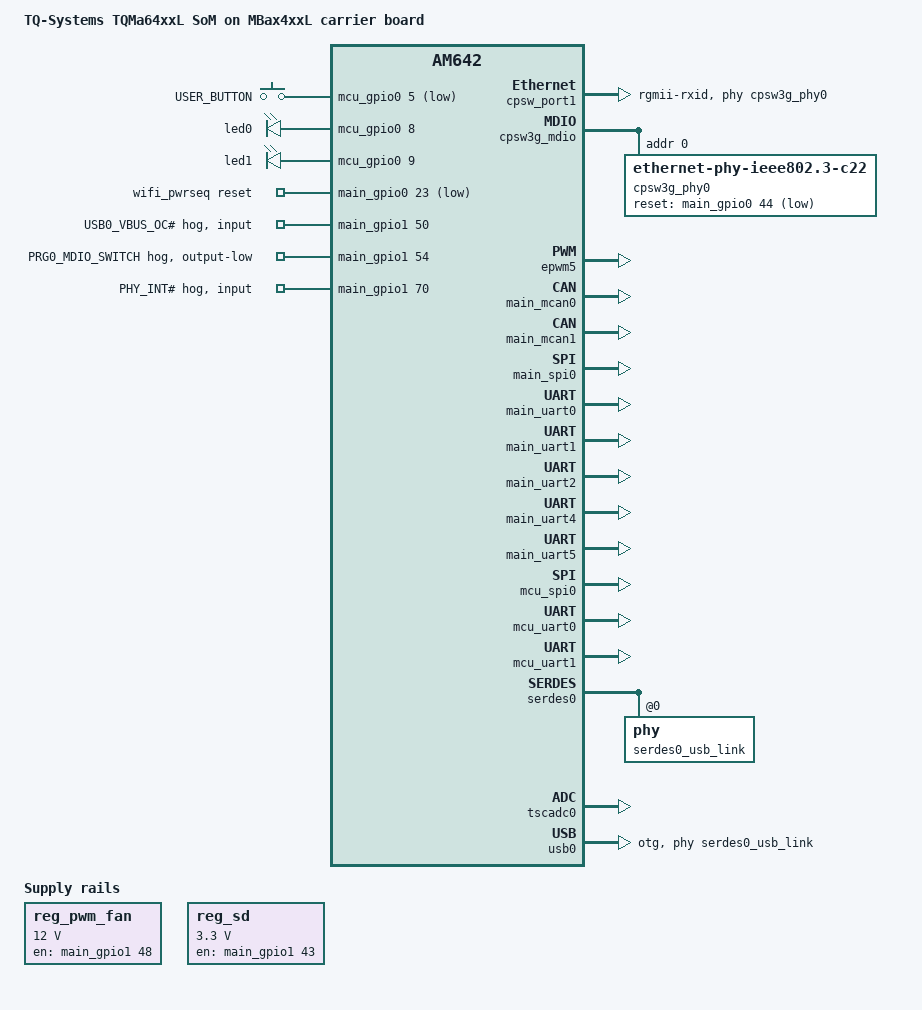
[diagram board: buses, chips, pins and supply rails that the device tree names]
/dts-v1/;
#include <dt-bindings/gpio/gpio.h>
#include <dt-bindings/input/input.h>
#include <dt-bindings/net/ti-dp83867.h>
#include <dt-bindings/phy/phy.h>
#include <dt-bindings/pwm/pwm.h>
#include "k3-serdes.h"
#include "k3-am642-tqma64xxl.dtsi"
/ {
	compatible = "tq,am642-tqma6442l-mbax4xxl", "tq,am642-tqma6442l",
		     "ti,am642";
	model = "TQ-Systems TQMa64xxL SoM on MBax4xxL carrier board";
	aliases {
		ethernet0 = &cpsw_port1;
		i2c1 = &mcu_i2c0;
		mmc1 = &sdhci1;
		serial0 = &mcu_uart0;
		serial1 = &mcu_uart1;
		serial2 = &main_uart0;
		serial3 = &main_uart1;
		serial4 = &main_uart2;
		serial5 = &main_uart4;
		serial6 = &main_uart5;
		serial7 = &main_uart3;
		spi1 = &main_spi0;
		spi2 = &mcu_spi0;
	};
	chosen {
		stdout-path = &main_uart0;
	};
	gpio-keys {
		compatible = "gpio-keys";
		pinctrl-names = "default";
		pinctrl-0 = <&mcu_gpio_keys_pins>;
		user-button {
			label = "USER_BUTTON";
			linux,code = <BTN_0>;
			gpios = <&mcu_gpio0 5 GPIO_ACTIVE_LOW>;
		};
	};
	gpio-leds {
		compatible = "gpio-leds";
		pinctrl-names = "default";
		pinctrl-0 = <&mcu_gpio_leds_pins>;
		led-0 {
			label = "led0";
			gpios = <&mcu_gpio0 8 GPIO_ACTIVE_HIGH>;
		};
		led-1 {
			label = "led1";
			gpios = <&mcu_gpio0 9 GPIO_ACTIVE_HIGH>;
		};
	};
	fan0: pwm-fan {
		compatible = "pwm-fan";
		pinctrl-names = "default";
		pinctrl-0 = <&pwm_fan_pins>;
		fan-supply = <&reg_pwm_fan>;
		#cooling-cells = <2>;
		pwms = <&epwm5 0 40000 PWM_POLARITY_INVERTED>;
		cooling-levels = <0 32 64 128 196 240>;
		pulses-per-revolution = <2>;
		interrupt-parent = <&main_gpio1>;
		interrupts = <49 IRQ_TYPE_EDGE_FALLING>;
		status = "disabled";
	};
	wifi_pwrseq: pwrseq-wifi {
		compatible = "mmc-pwrseq-simple";
		pinctrl-names = "default";
		pinctrl-0 = <&main_mmc1_wifi_pwrseq_pins>;
		reset-gpios = <&main_gpio0 23 GPIO_ACTIVE_LOW>;
	};
	reg_pwm_fan: regulator-pwm-fan {
		compatible = "regulator-fixed";
		pinctrl-names = "default";
		pinctrl-0 = <&pwm_fan_reg_pins>;
		regulator-name = "FAN_PWR";
		regulator-min-microvolt = <12000000>;
		regulator-max-microvolt = <12000000>;
		gpio = <&main_gpio1 48 GPIO_ACTIVE_HIGH>;
		enable-active-high;
	};
	reg_sd: regulator-sd {
		compatible = "regulator-fixed";
		pinctrl-names = "default";
		pinctrl-0 = <&main_mmc1_reg_pins>;
		regulator-name = "V_3V3_SD";
		regulator-min-microvolt = <3300000>;
		regulator-max-microvolt = <3300000>;
		gpio = <&main_gpio1 43 GPIO_ACTIVE_HIGH>;
		enable-active-high;
	};
};
&cpsw3g {
	pinctrl-names = "default";
	pinctrl-0 = <&cpsw_pins>;
};
&cpsw_port1 {
	phy-mode = "rgmii-rxid";
	phy-handle = <&cpsw3g_phy0>;
};
&cpsw_port2 {
	status = "disabled";
};
&cpsw3g_mdio {
	pinctrl-names = "default";
	pinctrl-0 = <&cpsw_mdio_pins>;
	status = "okay";
	cpsw3g_phy0: ethernet-phy@0 {
		compatible = "ethernet-phy-ieee802.3-c22";
		reg = <0>;
		reset-gpios = <&main_gpio0 44 GPIO_ACTIVE_LOW>;
		reset-assert-us = <1000>;
		reset-deassert-us = <1000>;
		ti,rx-fifo-depth = <DP83867_PHYCR_FIFO_DEPTH_4_B_NIB>;
		ti,tx-fifo-depth = <DP83867_PHYCR_FIFO_DEPTH_4_B_NIB>;
		ti,rx-internal-delay = <DP83867_RGMIIDCTL_2_00_NS>;
		ti,clk-output-sel = <DP83867_CLK_O_SEL_OFF>;
	};
};
&epwm5 {
	pinctrl-names = "default";
	pinctrl-0 = <&epwm5_pins>;
	status = "okay";
};
&main_gpio0 {
	pinctrl-names = "default";
	pinctrl-0 = <&main_gpio0_digital_pins>,
		    <&main_gpio0_hog_pins>;
	gpio-line-names =
		"", "", "", "",  
		"", "", "", "",  
		"", "", "", "",  
		"", "", "", "",  
		"", "", "", "",  
		"", "", "", "",  
		"", "", "EN_DIG_OUT_1", "STATUS_OUT_1",  
		"EN_DIG_OUT_2", "STATUS_OUT_2", "EN_SIG_OUT_3", "",  
		"", "", "STATUS_OUT_3", "EN_DIG_OUT_4",  
		"", "", "STATUS_OUT_4", "DIG_IN_1",  
		"DIG_IN_2", "DIG_IN_3", "DIG_IN_4";  
};
&main_gpio1 {
	pinctrl-names = "default";
	pinctrl-0 = <&main_gpio1_hog_pins>;
	gpio-line-names =
		"", "", "", "",  
		"", "", "", "",  
		"", "", "", "",  
		"", "", "", "",  
		"", "", "", "",  
		"", "", "", "",  
		"", "", "", "",  
		"", "", "", "",  
		"", "", "", "",  
		"", "", "", "",  
		"", "", "", "",  
		"", "", "", "",  
		"", "", "", "",  
		"", "", "", "ADC_SYNC",  
		"", "", "ADC_RST#", "ADC_DATA_RDY",  
		"", "", "", "",  
		"", "", "", "ADC_INT#",  
		"BG95_PWRKEY", "BG95_RESET";  
	line50-hog {
		gpio-hog;
		gpios = <50 0>;
		line-name = "USB0_VBUS_OC#";
		input;
	};
	line54-hog {
		gpio-hog;
		gpios = <54 0>;
		line-name = "PRG0_MDIO_SWITCH";
		output-low;
	};
	line70-hog {
		gpio-hog;
		gpios = <70 0>;
		line-name = "PHY_INT#";
		input;
	};
};
&main_mcan0 {
	pinctrl-names = "default";
	pinctrl-0 = <&main_mcan0_pins>;
	status = "okay";
};
&main_mcan1 {
	pinctrl-names = "default";
	pinctrl-0 = <&main_mcan1_pins>;
	status = "okay";
};
&main_spi0 {
	pinctrl-names = "default";
	pinctrl-0 = <&main_spi0_pins>;
	ti,pindir-d0-out-d1-in;
	status = "okay";
};
&main_uart0 {
	pinctrl-names = "default";
	pinctrl-0 = <&main_uart0_pins>;
	status = "okay";
};
&main_uart1 {
	pinctrl-names = "default";
	pinctrl-0 = <&main_uart1_pins>;
	status = "okay";
};
&main_uart2 {
	pinctrl-names = "default";
	pinctrl-0 = <&main_uart2_pins>;
	linux,rs485-enabled-at-boot-time;
	rs485-rts-active-low;
	status = "okay";
};
&main_uart3 {
	pinctrl-names = "default";
	pinctrl-0 = <&main_uart3_pins>;
};
&main_uart4 {
	pinctrl-names = "default";
	pinctrl-0 = <&main_uart4_pins>;
	status = "okay";
};
&main_uart5 {
	pinctrl-names = "default";
	pinctrl-0 = <&main_uart5_pins>;
	status = "okay";
};
&main0_thermal {
	trips {
		main0_active0: trip-active0 {
			temperature = <40000>;
			hysteresis = <5000>;
			type = "active";
		};
		main0_active1: trip-active1 {
			temperature = <48000>;
			hysteresis = <3000>;
			type = "active";
		};
		main0_active2: trip-active2 {
			temperature = <60000>;
			hysteresis = <10000>;
			type = "active";
		};
	};
	cooling-maps {
		map1 {
			trip = <&main0_active0>;
			cooling-device = <&fan0 1 1>;
		};
		map2 {
			trip = <&main0_active1>;
			cooling-device = <&fan0 2 2>;
		};
		map3 {
			trip = <&main0_active2>;
			cooling-device = <&fan0 3 3>;
		};
	};
};
&main1_thermal {
	trips {
		main1_active0: trip-active0 {
			temperature = <40000>;
			hysteresis = <5000>;
			type = "active";
		};
		main1_active1: trip-active1 {
			temperature = <48000>;
			hysteresis = <3000>;
			type = "active";
		};
		main1_active2: trip-active2 {
			temperature = <60000>;
			hysteresis = <10000>;
			type = "active";
		};
	};
	cooling-maps {
		map1 {
			trip = <&main1_active0>;
			cooling-device = <&fan0 1 1>;
		};
		map2 {
			trip = <&main1_active1>;
			cooling-device = <&fan0 2 2>;
		};
		map3 {
			trip = <&main1_active2>;
			cooling-device = <&fan0 3 3>;
		};
	};
};
&mcu_gpio0 {
	pinctrl-names = "default";
	pinctrl-0 = <&mcu_gpio0_pins>;
};
&mcu_i2c0 {
	pinctrl-names = "default";
	pinctrl-0 = <&mcu_i2c0_pins>;
};
&mcu_spi0 {
	pinctrl-names = "default";
	pinctrl-0 = <&mcu_spi0_pins>;
	ti,pindir-d0-out-d1-in;
	status = "okay";
};
&mcu_uart0 {
	pinctrl-names = "default";
	pinctrl-0 = <&mcu_uart0_pins>;
	status = "okay";
};
&mcu_uart1 {
	pinctrl-names = "default";
	pinctrl-0 = <&mcu_uart1_pins>;
	status = "okay";
};
&serdes_ln_ctrl {
	idle-states = <AM64_SERDES0_LANE0_USB>;
};
&serdes0 {
	serdes0_usb_link: phy@0 {
		reg = <0>;
		#phy-cells = <0>;
		resets = <&serdes_wiz0 1>;
		cdns,num-lanes = <1>;
		cdns,phy-type = <PHY_TYPE_USB3>;
	};
};
&sdhci1 {
	pinctrl-names = "default";
	pinctrl-0 = <&main_mmc1_pins>;
	bus-width = <4>;
	cd-gpios = <&main_gpio1 77 GPIO_ACTIVE_LOW>;
	disable-wp;
	no-mmc;
	ti,driver-strength-ohm = <50>;
	ti,fails-without-test-cd;
	status = "disabled";
};
&tscadc0 {
	status = "okay";
	adc {
		ti,adc-channels = <0 1 2 3 4 5 6 7>;
	};
};
&usb0 {
	pinctrl-names = "default";
	pinctrl-0 = <&main_usb0_pins>;
	dr_mode = "otg";
	maximum-speed = "super-speed";
	phys = <&serdes0_usb_link>;
	phy-names = "cdns3,usb3-phy";
};
&usbss0 {
	ti,vbus-divider;
};
&main_pmx0 {
	cpsw_pins: cpsw-pins {
		pinctrl-single,pins = <
			AM64X_IOPAD(0x01cc, PIN_INPUT, 4)
			AM64X_IOPAD(0x01d4, PIN_INPUT, 4)
			AM64X_IOPAD(0x01d8, PIN_INPUT, 4)
			AM64X_IOPAD(0x01f4, PIN_INPUT, 4)
			AM64X_IOPAD(0x0188, PIN_INPUT, 4)
			AM64X_IOPAD(0x0184, PIN_INPUT, 4)
			AM64X_IOPAD(0x0124, PIN_OUTPUT, 4)
			AM64X_IOPAD(0x012c, PIN_OUTPUT, 4)
			AM64X_IOPAD(0x0130, PIN_OUTPUT, 4)
			AM64X_IOPAD(0x014c, PIN_OUTPUT, 4)
			AM64X_IOPAD(0x00e0, PIN_OUTPUT, 4)
			AM64X_IOPAD(0x00dc, PIN_OUTPUT, 4)
		>;
	};
	cpsw_mdio_pins: cpsw-mdio-pins {
		pinctrl-single,pins = <
			AM64X_IOPAD(0x00b4, PIN_OUTPUT, 7)
			AM64X_IOPAD(0x01fc, PIN_OUTPUT, 4)
			AM64X_IOPAD(0x01f8, PIN_INPUT, 4)
		>;
	};
	epwm5_pins: epwm5-pins {
		pinctrl-single,pins = <
			AM64X_IOPAD(0x0098, PIN_OUTPUT, 3)
		>;
	};
	main_gpio0_digital_pins: main-gpio0-digital-pins {
		pinctrl-single,pins = <
			AM64X_IOPAD(0x0068, PIN_OUTPUT, 7)
			AM64X_IOPAD(0x006c, PIN_INPUT, 7)
			AM64X_IOPAD(0x0070, PIN_OUTPUT, 7)
			AM64X_IOPAD(0x0074, PIN_INPUT, 7)
			AM64X_IOPAD(0x0078, PIN_OUTPUT, 7)
			AM64X_IOPAD(0x008c, PIN_INPUT, 7)
			AM64X_IOPAD(0x0090, PIN_OUTPUT, 7)
			AM64X_IOPAD(0x009c, PIN_INPUT, 7)
			AM64X_IOPAD(0x00a0, PIN_INPUT, 7)
			AM64X_IOPAD(0x00a4, PIN_INPUT, 7)
			AM64X_IOPAD(0x00a8, PIN_INPUT, 7)
			AM64X_IOPAD(0x00ac, PIN_INPUT, 7)
		>;
	};
	main_gpio0_hog_pins: main-gpio0-hog-pins {
		pinctrl-single,pins = <
			AM64X_IOPAD(0x00b0, PIN_OUTPUT, 7)
		>;
	};
	main_gpio1_hog_pins: main-gpio1-hog-pins {
		pinctrl-single,pins = <
			AM64X_IOPAD(0x0228, PIN_INPUT, 7)
			AM64X_IOPAD(0x0238, PIN_OUTPUT, 7)
			AM64X_IOPAD(0x0278, PIN_INPUT, 7)
		>;
	};
	main_mcan0_pins: main-mcan0-pins {
		pinctrl-single,pins = <
			AM64X_IOPAD(0x0254, PIN_INPUT, 0)
			AM64X_IOPAD(0x0250, PIN_OUTPUT, 0)
		>;
	};
	main_mcan1_pins: main-mcan1-pins {
		pinctrl-single,pins = <
			AM64X_IOPAD(0x025c, PIN_INPUT, 0)
			AM64X_IOPAD(0x0258, PIN_OUTPUT, 0)
		>;
	};
	main_mmc1_pins: main-mmc1-pins {
		pinctrl-single,pins = <
			AM64X_IOPAD(0x0294, PIN_INPUT, 0)
			AM64X_IOPAD(0x028c, PIN_INPUT, 0)
			AM64X_IOPAD(0x0288, PIN_INPUT, 0)
			AM64X_IOPAD(0x0284, PIN_INPUT, 0)
			AM64X_IOPAD(0x0280, PIN_INPUT, 0)
			AM64X_IOPAD(0x027c, PIN_INPUT, 0)
			AM64X_IOPAD(0x0298, PIN_INPUT, 7)
			AM64X_IOPAD(0x0290, PIN_INPUT, 0)
		>;
	};
	main_mmc1_reg_pins: main-mmc1-reg-pins {
		pinctrl-single,pins = <
			AM64X_IOPAD(0x020c, PIN_OUTPUT, 7)
		>;
	};
	main_mmc1_wifi_pwrseq_pins: main-mmc1-wifi-pwrseq-pins {
		pinctrl-single,pins = <
			AM64X_IOPAD(0x005c, PIN_OUTPUT, 7)
		>;
	};
	main_spi0_pins: main-spi0-pins {
		pinctrl-single,pins = <
			AM64X_IOPAD(0x0210, PIN_OUTPUT, 0)
			AM64X_IOPAD(0x0208, PIN_OUTPUT, 0)
			AM64X_IOPAD(0x0214, PIN_OUTPUT, 0)
			AM64X_IOPAD(0x0218, PIN_INPUT, 0)
		>;
	};
	main_spi0_adc_pins: main-spi0-adc-pins {
		pinctrl-single,pins = <
			AM64X_IOPAD(0x023c, PIN_INPUT, 7)
			AM64X_IOPAD(0x0248, PIN_OUTPUT, 7)
			AM64X_IOPAD(0x024c, PIN_INPUT, 7)
			AM64X_IOPAD(0x026c, PIN_INPUT, 7)
		>;
	};
	main_uart0_pins: main-uart0-pins {
		pinctrl-single,pins = <
			AM64X_IOPAD(0x0230, PIN_INPUT, 0)
			AM64X_IOPAD(0x0234, PIN_OUTPUT, 0)
		>;
	};
	main_uart1_pins: main-uart1-pins {
		pinctrl-single,pins = <
			AM64X_IOPAD(0x0240, PIN_INPUT, 0)
			AM64X_IOPAD(0x0244, PIN_OUTPUT, 0)
		>;
	};
	main_uart2_pins: main-uart2-pins {
		pinctrl-single,pins = <
			AM64X_IOPAD(0x0044, PIN_OUTPUT, 2)
			AM64X_IOPAD(0x003c, PIN_INPUT, 2)
			AM64X_IOPAD(0x0040, PIN_OUTPUT, 2)
		>;
	};
	main_uart3_pins: main-uart3-pins {
		pinctrl-single,pins = <
			AM64X_IOPAD(0x0060, PIN_INPUT, 2)
			AM64X_IOPAD(0x0050, PIN_OUTPUT, 2)
			AM64X_IOPAD(0x0048, PIN_INPUT, 2)
			AM64X_IOPAD(0x004c, PIN_OUTPUT, 2)
		>;
	};
	main_uart4_pins: main-uart4-pins {
		pinctrl-single,pins = <
			AM64X_IOPAD(0x0064, PIN_INPUT, 2)
			AM64X_IOPAD(0x007c, PIN_OUTPUT, 2)
			AM64X_IOPAD(0x0054, PIN_INPUT, 2)
			AM64X_IOPAD(0x0058, PIN_OUTPUT, 2)
			AM64X_IOPAD(0x0270, PIN_OUTPUT, 7)
			AM64X_IOPAD(0x0274, PIN_OUTPUT, 7)
		>;
	};
	main_uart5_pins: main-uart5-pins {
		pinctrl-single,pins = <
			AM64X_IOPAD(0x0084, PIN_INPUT, 2)
			AM64X_IOPAD(0x0088, PIN_OUTPUT, 2)
		>;
	};
	main_usb0_pins: main-usb0-pins {
		pinctrl-single,pins = <
			AM64X_IOPAD(0x02a8, PIN_OUTPUT, 0)
		>;
	};
	pru_icssg1_mdio_pins: pru-icssg1-mdio-pins {
		pinctrl-single,pins = <
			AM64X_IOPAD(0x022c, PIN_OUTPUT, 7)
			AM64X_IOPAD(0x021c, PIN_OUTPUT, 7)
			AM64X_IOPAD(0x015c, PIN_OUTPUT, 0)
			AM64X_IOPAD(0x0158, PIN_INPUT, 0)
		>;
	};
	pru_icssg1_rgmii1_pins: pru-icssg1-rgmii1-pins {
		pinctrl-single,pins = <
			AM64X_IOPAD(0x00b8, PIN_INPUT, 2)
			AM64X_IOPAD(0x00bc, PIN_INPUT, 2)
			AM64X_IOPAD(0x00c0, PIN_INPUT, 2)
			AM64X_IOPAD(0x00c4, PIN_INPUT, 2)
			AM64X_IOPAD(0x00d0, PIN_INPUT, 2)
			AM64X_IOPAD(0x00c8, PIN_INPUT, 2)
			AM64X_IOPAD(0x00e4, PIN_OUTPUT, 2)
			AM64X_IOPAD(0x00e8, PIN_OUTPUT, 2)
			AM64X_IOPAD(0x00ec, PIN_OUTPUT, 2)
			AM64X_IOPAD(0x00f0, PIN_OUTPUT, 2)
			AM64X_IOPAD(0x00f8, PIN_OUTPUT, 2)
			AM64X_IOPAD(0x00f4, PIN_OUTPUT, 2)
		>;
	};
	pru_icssg1_rgmii2_pins: pru-icssg1-rgmii2-pins {
		pinctrl-single,pins = <
			AM64X_IOPAD(0x0108, PIN_INPUT, 2)
			AM64X_IOPAD(0x010c, PIN_INPUT, 2)
			AM64X_IOPAD(0x0110, PIN_INPUT, 2)
			AM64X_IOPAD(0x0114, PIN_INPUT, 2)
			AM64X_IOPAD(0x0120, PIN_INPUT, 2)
			AM64X_IOPAD(0x0118, PIN_INPUT, 2)
			AM64X_IOPAD(0x0134, PIN_OUTPUT, 2)
			AM64X_IOPAD(0x0138, PIN_OUTPUT, 2)
			AM64X_IOPAD(0x013c, PIN_OUTPUT, 2)
			AM64X_IOPAD(0x0140, PIN_OUTPUT, 2)
			AM64X_IOPAD(0x0148, PIN_OUTPUT, 2)
			AM64X_IOPAD(0x0144, PIN_OUTPUT, 2)
		>;
	};
	pwm_fan_pins: pwm-fan-pins {
		pinctrl-single,pins = <
			AM64X_IOPAD(0x0094, PIN_OUTPUT, 3)
			AM64X_IOPAD(0x0224, PIN_INPUT, 7)
		>;
	};
	pwm_fan_reg_pins: pwm-fan-reg-pins {
		pinctrl-single,pins = <
			AM64X_IOPAD(0x0220, PIN_OUTPUT, 7)
		>;
	};
};
&mcu_pmx0 {
	mcu_gpio_keys_pins: mcu-gpio-keys-pins {
		pinctrl-single,pins = <
			AM64X_MCU_IOPAD(0x0014, PIN_INPUT, 7)
		>;
	};
	mcu_gpio_leds_pins: mcu-gpio-leds-pins {
		pinctrl-single,pins = <
			AM64X_MCU_IOPAD(0x0020, PIN_OUTPUT, 7)
			AM64X_MCU_IOPAD(0x0024, PIN_OUTPUT, 7)
		>;
	};
	mcu_gpio0_pins: mcu-gpio0-pins {
		pinctrl-single,pins = <
			AM64X_MCU_IOPAD(0x0034, PIN_INPUT, 7)
			AM64X_MCU_IOPAD(0x0030, PIN_INPUT, 7)
			AM64X_MCU_IOPAD(0x0018, PIN_INPUT, 7)
			AM64X_MCU_IOPAD(0x001c, PIN_INPUT, 7)
			AM64X_MCU_IOPAD(0x0050, PIN_INPUT, 7)
			AM64X_MCU_IOPAD(0x0054, PIN_INPUT, 7)
		>;
	};
	mcu_i2c0_pins: mcu-i2c0-pins {
		pinctrl-single,pins = <
			AM64X_MCU_IOPAD(0x0048, PIN_INPUT, 0)
			AM64X_MCU_IOPAD(0x004c, PIN_INPUT, 0)
		>;
	};
	mcu_spi0_pins: mcu-spi0-pins {
		pinctrl-single,pins = <
			AM64X_MCU_IOPAD(0x0008, PIN_OUTPUT, 0)
			AM64X_MCU_IOPAD(0x0000, PIN_OUTPUT, 0)
			AM64X_MCU_IOPAD(0x0004, PIN_OUTPUT, 0)
			AM64X_MCU_IOPAD(0x000c, PIN_OUTPUT, 0)
			AM64X_MCU_IOPAD(0x0010, PIN_INPUT, 0)
		>;
	};
	mcu_uart0_pins: mcu-uart0-pins {
		pinctrl-single,pins = <
			AM64X_MCU_IOPAD(0x0028, PIN_INPUT, 0)
			AM64X_MCU_IOPAD(0x002c, PIN_OUTPUT, 0)
		>;
	};
	mcu_uart1_pins: mcu-uart1-pins {
		pinctrl-single,pins = <
			AM64X_MCU_IOPAD(0x0040, PIN_INPUT, 0)
			AM64X_MCU_IOPAD(0x0044, PIN_OUTPUT, 0)
			AM64X_MCU_IOPAD(0x0038, PIN_INPUT, 0)
			AM64X_MCU_IOPAD(0x003c, PIN_OUTPUT, 0)
		>;
	};
};
